# pse84 register map
Vendor: Infineon Technologies; Series: PSE84; File version: 1.0
CPU: CM33 r0p1, little endian, MPU, FPU, VTOR, 3 interrupt priority bits
Registers are 32-bit, read-write, reset 0x0 unless marked. A register's access mark holds for its fields unless they carry their own. Offsets are from the block's base; [hi:lo] are bit positions; lines under a group give offsets from that group; {n}, {i} and the like mark numbered series; 'fields as' and 'values as' point back to an identical list; <NAME> marks a mode.

## I3C (part 3 of 3) — I3C controller top
Base 0x42A50000
0x400 CTRL — I3C Block Control
  [31] ENABLED — I3C Block Pre-Enable When disabled, all write accesses to the I3C configuration registeres are ignored. Enable this preior to starting the configuration of the I3C block. Values: 0x0: Disable the I3C block 0x1: Pre-Enable the I3C block
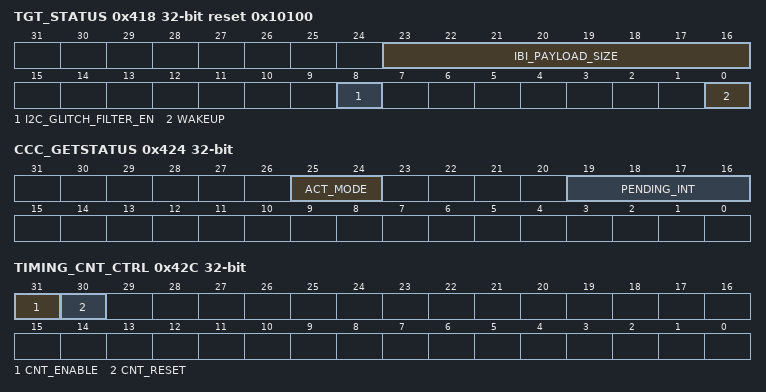
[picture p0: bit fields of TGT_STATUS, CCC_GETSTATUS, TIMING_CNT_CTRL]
0x418 TGT_STATUS ro reset 0x10100 — This register provides additional status information when functioning as a Target.
  [23:16] IBI_PAYLOAD_SIZE
  [8] I2C_GLITCH_FILTER_EN — <HIDDEN>
  [0] WAKEUP
0x424 CCC_GETSTATUS — This register provides additional information on GETSTATUS CCCs received when functioning as a Target.
  [25:24] ACT_MODE, [19:16] PENDING_INT
0x42C TIMING_CNT_CTRL — Controls the Counter used for timestamping I3C-relevant events, especially when communicating with Asynchronous Timing Control Mode 0 enabled.
  [31] CNT_ENABLE, [30] CNT_RESET
0x430 TIMING_CNT0 ro — Most Significant Bits of the Counter
  [31:0] TIMING_COUNTER_MSB
0x434 TIMING_CNT1 ro — Least Significant Bits of the Counter
  [31:0] TIMING_COUNTER_LSB

## PD — Power Domain Controller
Base 0x44103000
0x00 CTL — Power Domain Control
  [0] BLEED_EN — Activates bleed feature for the controlled power domain
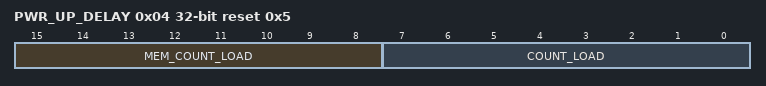
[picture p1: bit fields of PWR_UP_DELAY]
0x04 PWR_UP_DELAY reset 0x5 — Active switch weak enable to active switch strong enable delay
  [15:8] MEM_COUNT_LOAD — Load value for counter running on clk_pwr (10MHz) providing the timing from weak MEM switch enable to strong MEM switch enable. Default is 5 for ~500ns
  [7:0] COUNT_LOAD — Load value for counter running on clk_pwr (10MHz) providing the timing from weak ACTIVE switch enable to strong ACTIVE switch enable. Default is 5 for ~500ns

## MS_CTL — Master control registers
Base 0x441C4000
{0x0+0x10*i} MS[{i}] (i=0..28) group — Master protection context control
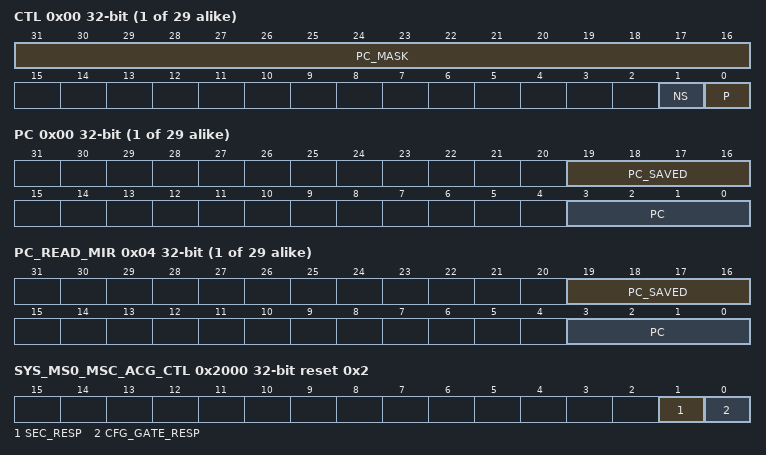
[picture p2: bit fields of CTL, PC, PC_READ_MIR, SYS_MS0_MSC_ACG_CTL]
  0x00 CTL — Master 'x' protection context control
    [31:16] PC_MASK — Protection context mask for protection contexts '15' down to '0'. Bit PC_MASK[i] indicates if the MS_PC_STRUCT[x].PC[3:0] protection context field can be set to the value 'i': - PC_MASK[i] is '0': MS_PC_STRUCT[x].PC[3:0] can NOT be set to 'i'; and PC[3:0] is not changed. - PC_MASK[i] is '1': MS_PC_STRUCT[x].PC[3:0] can be set to 'i'. Note: When CM33_0 CM33_PC_CTL.VALID[i] is '1' (the associated protection context handler is valid), write transfers to PC_MASK[i] always write '0', regardless of data written. This ensures that when valid protection context handlers are used to enter protection contexts 0, 1, 2 or 3 through HW (HW modifies MS_PC_STRUCT[x].PC[3:0] on entry of the handler), it is NOT possible for SW to enter those protection contexts.
    [1] NS — Master security controller configuration. 0: Bus master is secure. Master can send both secure and non-secure transfers. Accesses to secure addresses are not blocked and the security flag, HNONSEC, is set accordingly. 1: Bus master is non-secure. Master can send only non-secure transfers. Access to secure addresses, that is, outside the Uncheck regions, are blocked.
    [0] P — Privileged setting ('0': user mode; '1': privileged mode). Notes: This field is ONLY used for masters that do NOT provide their own user/privileged access control attribute. The default/reset field value provides privileged mode access capabilities.
{0x1000+0x10*i} MS_PC[{i}] (i=0..28) group — Master protection context value
  0x00 PC — Master 'x' protection context value
    [19:16] PC_SAVED
    [3:0] PC — Active protection context (PC). Modifications to this field are constrained by the associated MS_CTL_STRUCT[x].CTL.PC_MASK value. PC[3:0] can be set to 'i' only if the corresponding mask bit (PC_MASK[i]) is '1'. Note: When the APPCPUSS works with the M33SYSCPUSS, PCx_HANDLER is NOT implemented as CM33_0_PC_CTL.VALID[3:0] is exported to the APPCPUSS to clear PC_MASK[i] of the APPCPUSS masters.
  0x04 PC_READ_MIR ro — Master 'x' protection context value read mirror register
    [19:16] PC_SAVED — Read-only mirror of PC.PC_SAVED
    [3:0] PC — Read-only mirror of PC.PC
0x2000 SYS_MS0_MSC_ACG_CTL reset 0x2 — SYS_MS0 master security Controller & ACG configuration
  [1] SEC_RESP — Reseponse type when transfers are not allowed by MSC. 0: Read as zero, write ignore. 1: Error response.
  [0] CFG_GATE_RESP — Response type when the ACG is blocking the incoming transfers: 0: Waited transfer 1: Error response
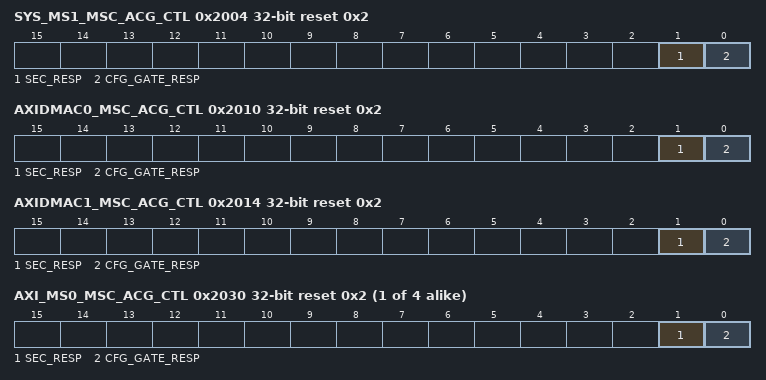
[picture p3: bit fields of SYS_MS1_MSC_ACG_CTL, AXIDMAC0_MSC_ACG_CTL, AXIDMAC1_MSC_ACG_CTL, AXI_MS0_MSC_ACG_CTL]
0x2004 SYS_MS1_MSC_ACG_CTL reset 0x2 — SYS_MS1 master security Controller & ACG configuration
  fields as SYS_MS0_MSC_ACG_CTL
0x2010 AXIDMAC0_MSC_ACG_CTL reset 0x2 — AXI DMAC0 MSC and ACG configuration
  fields as SYS_MS0_MSC_ACG_CTL
0x2014 AXIDMAC1_MSC_ACG_CTL reset 0x2 — AXI DMAC1 MSC and ACG configuration
  fields as SYS_MS0_MSC_ACG_CTL
{0x2030+4i} AXI_MS{i}_MSC_ACG_CTL reset 0x2 (i=0..3) — AXI_MS{i} master security Controller & ACG configuration
  fields as SYS_MS0_MSC_ACG_CTL
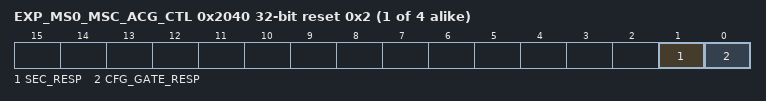
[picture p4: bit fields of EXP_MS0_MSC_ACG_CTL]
{0x2040+4i} EXP_MS{i}_MSC_ACG_CTL reset 0x2 (i=0..3) — EXP_MS{i} master security Controller & ACG configuration
  fields as SYS_MS0_MSC_ACG_CTL

## APPCPUSS_SL_CTL — APPCPUSS Internal slave control registers
Base 0x441C8000
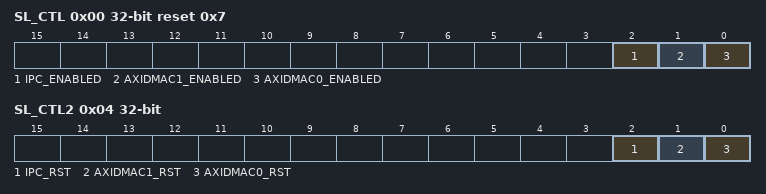
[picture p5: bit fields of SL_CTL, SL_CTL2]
0x00 SL_CTL reset 0x7 — Slave control (Clock enables)
  [2] IPC_ENABLED — 0: IPC disabled 1: IPC enabled
  [1] AXIDMAC1_ENABLED — 0: AXI DMAC1 disabled 1: AXI DMAC1 enabled
  [0] AXIDMAC0_ENABLED — Slave enable controls. Each bit indicates whether the respective slave is enabled or not. 0: Disabled 1: Enabled If the slave is disabled, its clock is gated off (constant '0'). Any access (MMIO AHB access) to slave when disabled result in AHB error response.
0x04 SL_CTL2 — Slave control2 (Reset enables)
  [2] IPC_RST — 0: IPC reset disabled 1: IPC reset enabled
  [1] AXIDMAC1_RST — 0: AXI DMAC1 reset disabled 1: AXI DMAC1 reset enabled
  [0] AXIDMAC0_RST — Slave reset controls. Each bit indicates whether the respective slave reset is enabled or not. 0: Disabled 1: Enabled If the slave is under reset enabled state, its clock is gated off (constant '0') and its resets are in activated state (rst_n = 0) Any access (MMIO AHB access) to slave when disabled result in AHB error response.

## SDHC0 (part 1 of 3) — SD/eMMC Host Controller
Base 0x44810000
Same registers: SDHC1 0x44820000
0x00 WRAP group — MMIO at SDHC wrapper level
  0x00 CTL — Top level wrapper control
    [31] ENABLE — IP Enable: 0: IP disabled, RAM in DeepSleep, SDHC_CORE regs are inaccessible (any attempts to access will result in AHB Error responses), IP is NOT held in reset but the clocks are gated 1: IP enabled, normal operation
